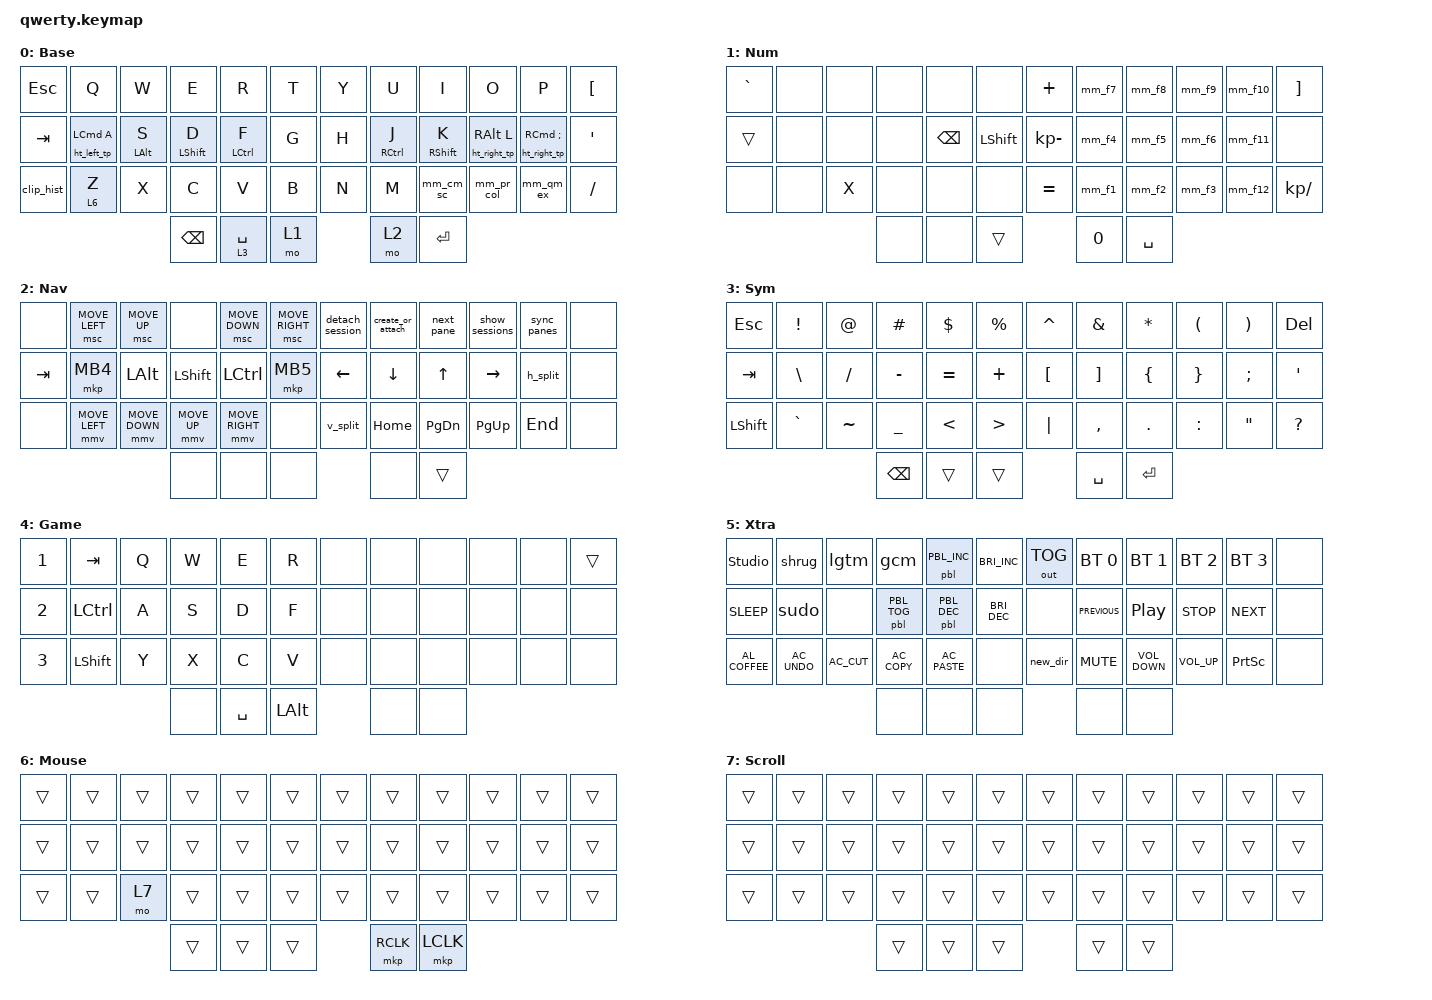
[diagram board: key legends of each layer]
/* upstream bindings and behaviors */
#include <behaviors.dtsi>
#include <dt-bindings/zmk/bt.h>
#include <dt-bindings/zmk/keys.h>
#include <dt-bindings/zmk/mouse.h>
#include <dt-bindings/zmk/outputs.h>
#include <behaviors/mouse_keys.dtsi>
#include <dt-bindings/zmk/ext_power.h>

/* local overlays */
#include "keymap_features/prospector_brightness.dtsi"
#include "keymap_features/macros.dtsi"
#include "keymap_features/behaviors.dtsi"
#include "keymap_features/combos.dtsi"

/ {
/* --- KEYMAP CONFIG --- */
// ╭──────┬──────┬──────┬──────┬──────┬──────╮  ╭──────┬──────┬──────┬──────┬──────┬──────╮
//    00     01     02     03    04      05        06     07     08     09     10     11
// ├──────┼──────┼──────┼──────┼──────┼──────┤  ├──────┼──────┼──────┼──────┼──────┼──────┤
//    12     13     14     15    16      17        18     19     20     21     22     23
// ├──────┼──────┼──────┼──────┼──────┼──────┤  ├──────┼──────┼──────┼──────┼──────┼──────┤
//    24     25     26     27    28      29        30     31     32     33     34     35
// ╰──────┴──────┴──────┼──────┼──────┼──────┤  ├──────┼──────┼──────┴──────┴──────┴──────╯
//                         36     37     38        39     40
//                      ╰──────┴──────┴──────╯  ╰──────┴──────╯
// #define BASE    0
// #define NUM     1
// #define NAV     2
// #define SYM     3
// #define GAME    4
// #define EXTRAS  5
// #define MOUSE   6
// #define SCROLL  7

// This shared keymap builds for prospector and non-prospector firmwares. 
// This stubs the key bindings that are contained in the prospector module
// so non-prospector firmware can build.
#ifndef CONFIG_SHIELD_PROSPECTOR_ADAPTER
    behaviors {
        /omit-if-no-ref/ pbl: prospector_brightness_stub {
            compatible = "zmk,behavior-macro-two-param";
            #binding-cells = <2>;
            bindings = <&none>;
        };
    };
#endif

    behaviors {
        // A stays Cmd. Hold Z for precision mouse mode; tap/quick-repeat for Z.
        lt_mouse: mouse_layer_tap {
            compatible = "zmk,behavior-hold-tap";
            #binding-cells = <2>;
            flavor = "hold-preferred";
            tapping-term-ms = <200>;
            quick-tap-ms = <175>;
            bindings = <&mo>, <&kp>;
        };
    };

    combos {
        // Z+X is now mouse mode + scroll, not the shared left-click combo.
        /delete-node/ combo_left_click;
        combo_middle_click { layers = <0>; };
        combo_right_click { layers = <0>; };
        combo_BASE_or_EXTRAS { layers = <0>; };
    };

    keymap {
        compatible = "zmk,keymap";
        BASE {
            display-name = "Base";
            bindings = <
// ╭───────────────┬────────────────┬────────────────┬─────────────────┬─────────────────┬──────╮  ╭──────┬──────────────────┬──────────────────┬─────────────────┬─────────────────┬─────────────╮
    &kp ESC          &kp Q            &kp W            &kp E             &kp R             &kp T    &kp Y   &kp U              &kp I              &kp O             &kp P           &kp LBKT
// ├───────────────┼────────────────┼────────────────┼─────────────────┼─────────────────┼──────┤  ├──────┼──────────────────┼──────────────────┼─────────────────┼─────────────────┼─────────────┤
    &kp TAB          &ht_left_tp LCMD A  &ht_left LALT S  &ht_left LSHFT D  &ht_left LCTRL F  &kp G    &kp H   &ht_right RCTRL J  &ht_right RSHFT K  &ht_right_tp RALT L  &ht_right_tp RCMD SEMICOLON   &kp SQT
// ├───────────────┼────────────────┼────────────────┼─────────────────┼─────────────────┼──────┤  ├──────┼──────────────────┼──────────────────┼─────────────────┼─────────────────┼─────────────┤
    &clip_hist       &lt_mouse 6 Z    &kp X            &kp C             &kp V             &kp B    &kp N   &kp M              &mm_cm_sc          &mm_pr_col        &mm_qm_ex          &kp FSLH
// ╰───────────────┴────────────────┴────────────────┼─────────────────┼─────────────────┼──────┤  ├──────┼──────────────────┼──────────────────┴─────────────────┴─────────────────┴─────────────╯
                                                             &kp BACKSPACE   &lt 3 SPACE   &mo 1             &mo 2      &kp ENTER
                                                         // ╰──────────────────┴─────────┴──────╯  ╰──────────┴──────────────╯
            >;
        };

        NUM {
            display-name = "Num";
            bindings = <
&kp GRAVE &none &none  &none  &none          &none            &kp PLUS     &mm_f7             &mm_f8             &mm_f9             &mm_f10            &kp RBKT
&trans   &none  &none  &none  &kp BACKSPACE  &kp LSHIFT       &kp KP_MINUS &mm_f4             &mm_f5             &mm_f6             &mm_f11            &none
&none    &none  &kp X  &none  &none          &none            &kp EQUAL    &mm_f1             &mm_f2             &mm_f3             &mm_f12            &kp KP_SLASH
                       &none  &none          &trans           &kp N0     &kp SPACE
            >;
        };

        NAV {
            display-name = "Nav";
            bindings = <
&none    &msc MOVE_LEFT  &msc MOVE_UP    &none        &msc MOVE_DOWN  &msc MOVE_RIGHT     &detach_session  &create_or_attach  &next_pane   &show_sessions  &sync_panes       &none
&kp TAB  &mkp MB4        &kp LALT        &kp LSHFT    &kp LCTRL       &mkp MB5            &kp LEFT_ARROW   &kp DOWN           &kp UP       &kp RIGHT_ARROW &h_split          &none
&none    &mmv MOVE_LEFT  &mmv MOVE_DOWN  &mmv MOVE_UP &mmv MOVE_RIGHT &none               &v_split         &kp HOME           &kp PG_DN    &kp PG_UP       &kp END           &none
                                                      &none   &none   &none               &none   &trans
            >;
        };

        SYM {
            display-name = "Sym";
            bindings = <
// Standard US punctuation; the host input source determines the printed symbols.
&kp ESC   &kp EXCLAMATION &kp AT    &kp HASH  &kp DLLR  &kp PRCNT    &kp CARET &kp AMPS  &kp ASTRK &kp LPAR  &kp RPAR      &kp DEL
&kp TAB   &kp BSLH        &kp FSLH  &kp MINUS &kp EQUAL &kp PLUS     &kp LBKT  &kp RBKT  &kp LBRC  &kp RBRC  &kp SEMICOLON &kp SQT
&kp LSHFT &kp GRAVE       &kp TILDE &kp UNDER &kp LT    &kp GT       &kp PIPE  &kp COMMA &kp DOT   &kp COLON &kp DQT       &kp QUESTION
                                  &kp BACKSPACE &trans &trans      &kp SPACE &kp ENTER
            >;
        };

        GAME {
            display-name = "Game";
            bindings = <
&kp N1  &kp TAB    &kp Q  &kp W   &kp E      &kp R           &none  &none  &none  &none  &none  &trans
&kp N2  &kp LCTRL  &kp A  &kp S   &kp D      &kp F           &none  &none  &none  &none  &none  &none
&kp N3  &kp LSHFT  &kp Y  &kp X   &kp C      &kp V           &none  &none  &none  &none  &none  &none
                          &none   &kp SPACE  &kp LEFT_ALT    &none  &none
            >;
        };

        EXTRAS {
            display-name = "Xtra";
            bindings = <
&studio_unlock    &shrug          &lgtm           &gcm            &pbl PBL_INC    &kp C_BRIGHTNESS_INC    &out OUT_TOG  &bt BT_SEL 0    &bt BT_SEL 1       &bt BT_SEL 2      &bt BT_SEL 3     &none
&kp C_SLEEP       &sudo           &none           &pbl PBL_TOG    &pbl PBL_DEC    &kp C_BRIGHTNESS_DEC    &none         &kp C_PREVIOUS  &kp C_PLAY_PAUSE   &kp C_STOP        &kp C_NEXT       &none
&kp C_AL_COFFEE   &kp C_AC_UNDO   &kp C_AC_CUT    &kp C_AC_COPY   &kp C_AC_PASTE  &none                   &new_dir      &kp K_MUTE      &kp C_VOLUME_DOWN  &kp C_VOLUME_UP   &kp PRINTSCREEN  &none
                                                                                   &none  &none  &none    &none         &none
            >;
        };

        MOUSE {
            display-name = "Mouse";
            // Layer 6 also selects the slow-pointer processor. Hold X to scroll.
            bindings = <
&trans &trans &trans &trans &trans &trans    &trans &trans &trans &trans &trans &trans
&trans &trans &trans &trans &trans &trans    &trans &trans &trans &trans &trans &trans
&trans &trans &mo 7  &trans &trans &trans    &trans &trans &trans &trans &trans &trans
                     &trans &trans &trans    &mkp RCLK &mkp LCLK
            >;
        };

        SCROLL {
            display-name = "Scroll";
            bindings = <
// ╭────────┬────────┬────────┬────────┬────────┬────────╮  ╭────────┬────────┬────────┬────────┬────────┬────────╮
    &trans    &trans   &trans   &trans   &trans   &trans      &trans   &trans   &trans   &trans   &trans   &trans
// ├────────┼────────┼────────┼────────┼────────┼────────┤  ├────────┼────────┼────────┼────────┼────────┼────────┤
    &trans    &trans   &trans   &trans   &trans   &trans      &trans   &trans   &trans   &trans   &trans   &trans
// ├────────┼────────┼────────┼────────┼────────┼────────┤  ├────────┼────────┼────────┼────────┼────────┼────────┤
    &trans    &trans   &trans   &trans   &trans   &trans      &trans   &trans   &trans   &trans   &trans   &trans
// ╰────────┴────────┴────────┼────────┼────────┼────────┤  ├────────┼────────┼────────┴────────┴────────┴────────╯
                                  &trans   &trans   &trans      &trans   &trans
                             // ╰────────┴────────┴────────╯  ╰────────┴────────╯
            >;
        };
    };
};
